VERSION ""

NS_ :

BS_:

BU_: TelemLeader IMU_FR IMU_Back IMU_FL Suspension_FR Suspension_Back Suspension_FL Suspension_Specials Pitot_FR Pitot_FL WheelRPM_FR WheelRPM_Back WheelRPM_FL RideHeight_FR RideHeight_Back RideHeight_FL Temp_Center Array

BO_ 2147487744 TelemLeader_Center: 2 TelemLeader
 SG_ Timestamp : 0|16@1+ (1,0) [0|65535] "" Vector__XXX

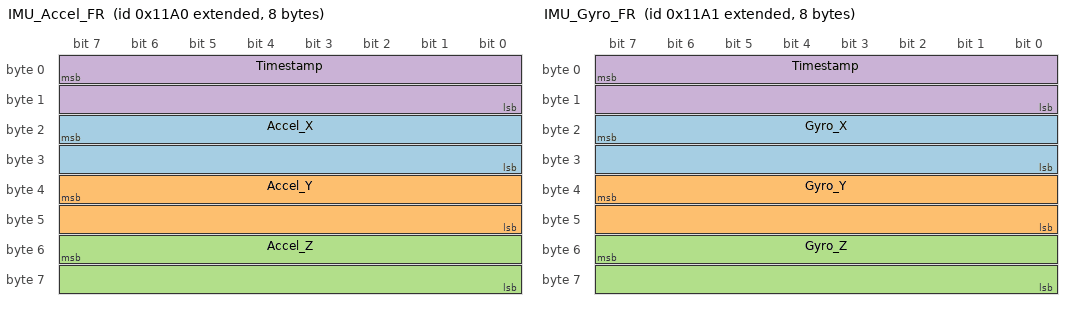
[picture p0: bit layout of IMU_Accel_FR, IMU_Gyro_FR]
BO_ 2147488160 IMU_Accel_FR: 8 IMU_FR
 SG_ Accel_X : 23|16@0- (0.000122,0) [-3.997696|3.997574] "g" Vector__XXX
 SG_ Accel_Y : 39|16@0- (0.000122,0) [-3.997696|3.997574] "g" Vector__XXX
 SG_ Accel_Z : 55|16@0- (0.000122,0) [-3.997696|3.997574] "g" Vector__XXX
 SG_ Timestamp : 7|16@0+ (1,0) [0|65535] "" Vector__XXX

BO_ 2147488161 IMU_Gyro_FR: 8 IMU_FR
 SG_ Gyro_X : 23|16@0- (0.00875,0) [-286.72|286.71125] "dps" Vector__XXX
 SG_ Gyro_Y : 39|16@0- (0.00875,0) [-286.72|286.71125] "dps" Vector__XXX
 SG_ Gyro_Z : 55|16@0- (0.00875,0) [-286.72|286.71125] "dps" Vector__XXX
 SG_ Timestamp : 7|16@0+ (1,0) [0|65535] "" Vector__XXX

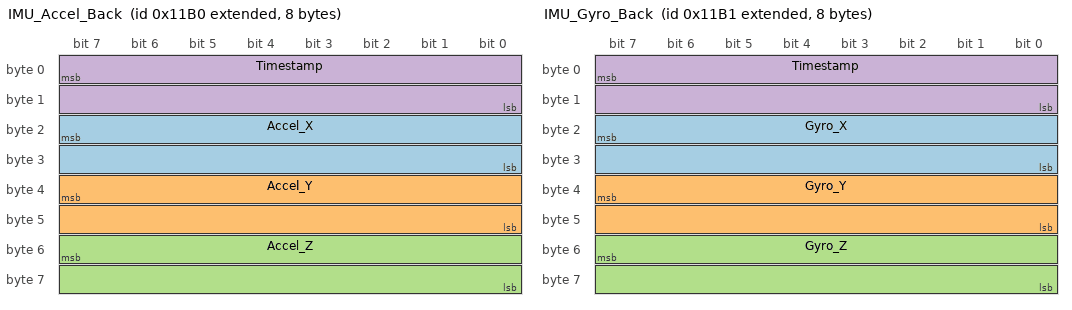
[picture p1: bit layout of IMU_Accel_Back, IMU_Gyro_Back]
BO_ 2147488176 IMU_Accel_Back: 8 IMU_Back
 SG_ Accel_X : 23|16@0- (0.000122,0) [-3.997696|3.997574] "" Vector__XXX
 SG_ Accel_Y : 39|16@0- (0.000122,0) [-3.997696|3.997574] "" Vector__XXX
 SG_ Accel_Z : 55|16@0- (0.000122,0) [-3.997696|3.997574] "" Vector__XXX
 SG_ Timestamp : 7|16@0+ (1,0) [0|65535] "" Vector__XXX

BO_ 2147488177 IMU_Gyro_Back: 8 IMU_Back
 SG_ Gyro_X : 23|16@0- (0.00875,0) [-286.72|286.71125] "" Vector__XXX
 SG_ Gyro_Y : 39|16@0- (0.00875,0) [-286.72|286.71125] "" Vector__XXX
 SG_ Gyro_Z : 55|16@0- (0.00875,0) [-286.72|286.71125] "" Vector__XXX
 SG_ Timestamp : 7|16@0+ (1,0) [0|65535] "" Vector__XXX

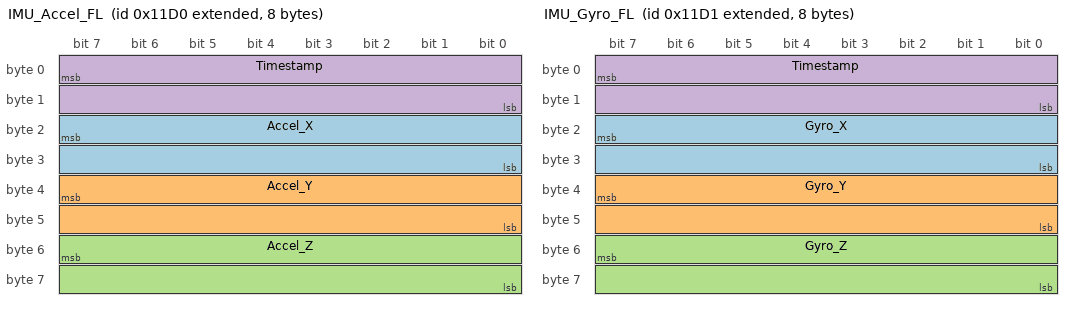
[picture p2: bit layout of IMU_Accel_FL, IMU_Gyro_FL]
BO_ 2147488208 IMU_Accel_FL: 8 IMU_FL
 SG_ Accel_X : 23|16@0- (0.000122,0) [-3.997696|3.997574] "" Vector__XXX
 SG_ Accel_Y : 39|16@0- (0.000122,0) [-3.997696|3.997574] "" Vector__XXX
 SG_ Accel_Z : 55|16@0- (0.000122,0) [-3.997696|3.997574] "" Vector__XXX
 SG_ Timestamp : 7|16@0+ (1,0) [0|65535] "" Vector__XXX

BO_ 2147488209 IMU_Gyro_FL: 8 IMU_FL
 SG_ Gyro_X : 23|16@0- (0.00875,0) [-286.72|286.71125] "" Vector__XXX
 SG_ Gyro_Y : 39|16@0- (0.00875,0) [-286.72|286.71125] "" Vector__XXX
 SG_ Gyro_Z : 55|16@0- (0.00875,0) [-286.72|286.71125] "" Vector__XXX
 SG_ Timestamp : 7|16@0+ (1,0) [0|65535] "" Vector__XXX

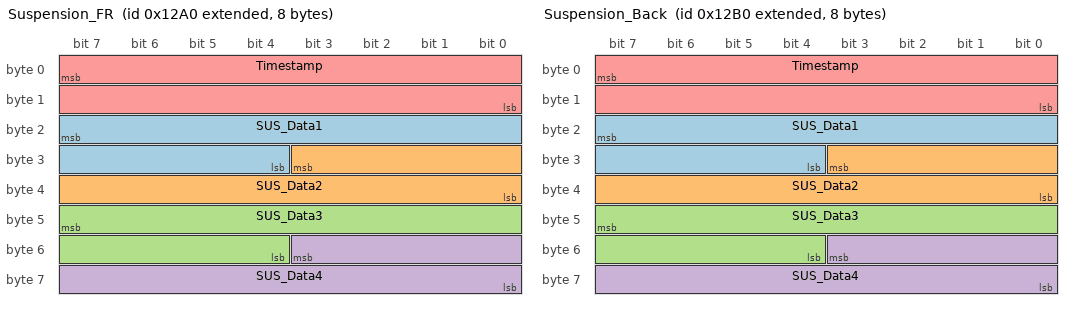
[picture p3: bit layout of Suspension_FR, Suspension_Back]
BO_ 2147488416 Suspension_FR: 8 Suspension_FR
 SG_ SUS_Data1 : 23|12@0+ (0.0188885,1) [0|78.367296] "mm" Vector__XXX
 SG_ SUS_Data2 : 27|12@0+ (0.0188885,1) [0|78.367296] "mm" Vector__XXX
 SG_ SUS_Data3 : 47|12@0+ (0.0188885,1) [0|78.367296] "mm" Vector__XXX
 SG_ SUS_Data4 : 51|12@0+ (0.0188885,1) [0|78.367296] "mm" Vector__XXX
 SG_ Timestamp : 7|16@0+ (1,0) [0|65535] "" Vector__XXX

BO_ 2147488432 Suspension_Back: 8 Suspension_Back
 SG_ SUS_Data1 : 23|12@0+ (0.0188885,1) [0|78.367296] "mm" Vector__XXX
 SG_ SUS_Data2 : 27|12@0+ (0.0188885,1) [0|78.367296] "mm" Vector__XXX
 SG_ SUS_Data3 : 47|12@0+ (0.0188885,1) [0|78.367296] "mm" Vector__XXX
 SG_ SUS_Data4 : 51|12@0+ (0.0188885,1) [0|78.367296] "mm" Vector__XXX
 SG_ Timestamp : 7|16@0+ (1,0) [0|65535] "" Vector__XXX

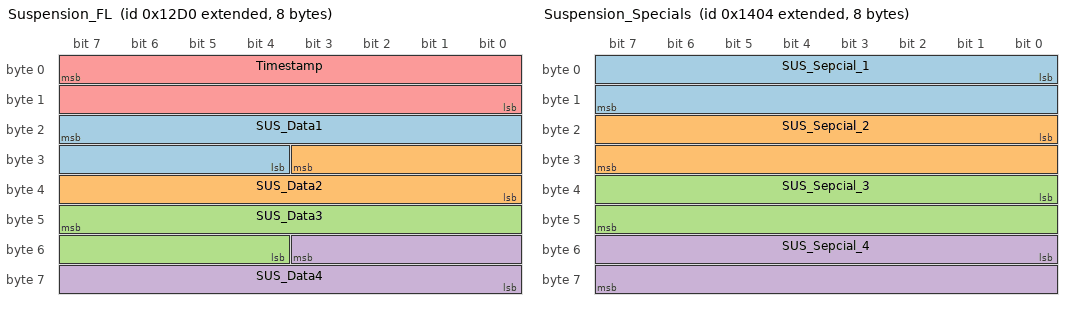
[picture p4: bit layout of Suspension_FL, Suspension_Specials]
BO_ 2147488464 Suspension_FL: 8 Suspension_FL
 SG_ SUS_Data1 : 23|12@0+ (0.0188885,1) [0|78.367296] "mm" Vector__XXX
 SG_ SUS_Data2 : 27|12@0+ (0.0188885,1) [0|78.367296] "mm" Vector__XXX
 SG_ SUS_Data3 : 47|12@0+ (0.0188885,1) [0|78.367296] "mm" Vector__XXX
 SG_ SUS_Data4 : 51|12@0+ (0.0188885,1) [0|78.367296] "mm" Vector__XXX
 SG_ Timestamp : 7|16@0+ (1,0) [0|65535] "" Vector__XXX

BO_ 2147488772 Suspension_Specials: 8 Suspension_Specials
 SG_ SUS_Sepcial_1 : 0|16@1+ (1,0) [0|65535] "" Vector__XXX
 SG_ SUS_Sepcial_2 : 16|16@1+ (1,0) [0|65535] "" Vector__XXX
 SG_ SUS_Sepcial_3 : 32|16@1+ (1,0) [0|65535] "" Vector__XXX
 SG_ SUS_Sepcial_4 : 48|16@1+ (1,0) [0|65535] "" Vector__XXX

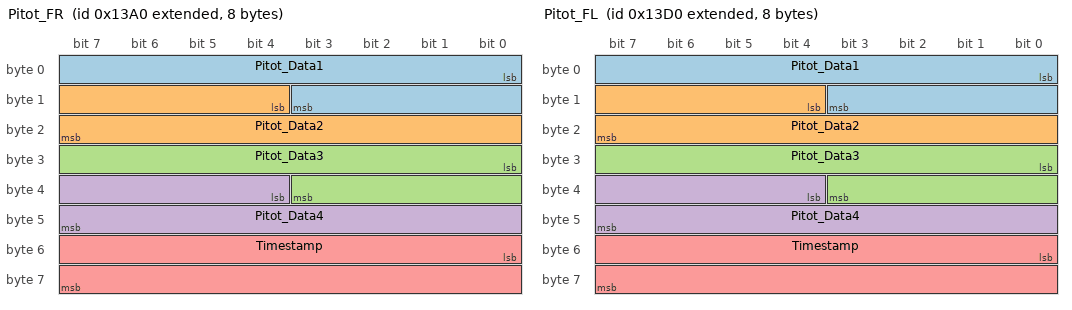
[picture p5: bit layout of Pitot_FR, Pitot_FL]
BO_ 2147488672 Pitot_FR: 8 Pitot_FR
 SG_ Pitot_Data1 : 0|12@1+ (1,0) [0|4095] "" Vector__XXX
 SG_ Pitot_Data2 : 12|12@1+ (1,0) [0|4095] "" Vector__XXX
 SG_ Pitot_Data3 : 24|12@1+ (1,0) [0|4095] "" Vector__XXX
 SG_ Pitot_Data4 : 36|12@1+ (1,0) [0|4095] "" Vector__XXX
 SG_ Timestamp : 48|16@1+ (1,0) [0|65535] "" Vector__XXX

BO_ 2147488720 Pitot_FL: 8 Pitot_FL
 SG_ Pitot_Data1 : 0|12@1+ (1,0) [0|4095] "" Vector__XXX
 SG_ Pitot_Data2 : 12|12@1+ (1,0) [0|4095] "" Vector__XXX
 SG_ Pitot_Data3 : 24|12@1+ (1,0) [0|4095] "" Vector__XXX
 SG_ Pitot_Data4 : 36|12@1+ (1,0) [0|4095] "" Vector__XXX
 SG_ Timestamp : 48|16@1+ (1,0) [0|65535] "" Vector__XXX

BO_ 2147488928 WheelRPM_FR: 8 WheelRPM_FR
 SG_ Timestamp : 7|16@0+ (1,0) [0|65535] "" Vector__XXX
 SG_ RPM : 23|16@0+ (1,0) [0|65535] "rpm" Vector__XXX

BO_ 2147488960 WheelRPM_Back: 4 WheelRPM_Back
 SG_ Timestamp : 7|16@0+ (1,0) [0|65535] "" Vector__XXX
 SG_ RPM : 23|16@0+ (1,0) [0|65535] "rpm" Vector__XXX

BO_ 2147488976 WheelRPM_FL: 8 WheelRPM_FL
 SG_ Timestamp : 7|16@0+ (1,0) [0|65535] "" Vector__XXX
 SG_ RPM : 23|16@0+ (1,0) [0|65535] "rpm" Vector__XXX

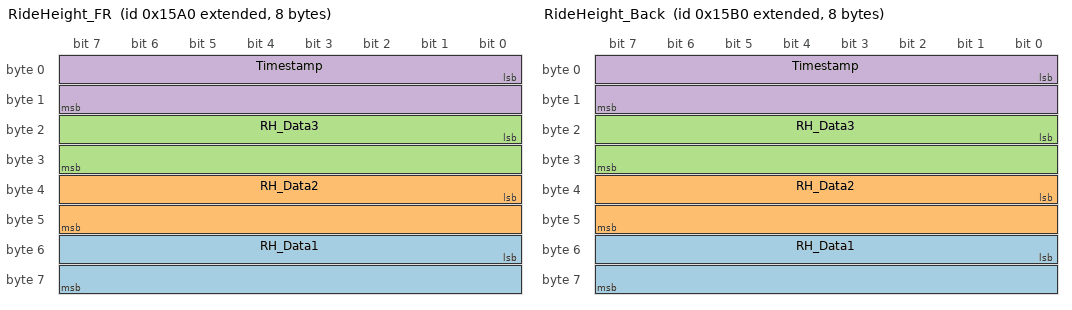
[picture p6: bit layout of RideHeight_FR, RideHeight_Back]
BO_ 2147489184 RideHeight_FR: 8 RideHeight_FR
 SG_ RH_Data1 : 48|16@1+ (0.01,0) [0|655.36] "cm" Vector__XXX
 SG_ RH_Data2 : 32|16@1+ (0.01,0) [0|655.36] "cm" Vector__XXX
 SG_ RH_Data3 : 16|16@1+ (0.01,0) [0|655.36] "cm" Vector__XXX
 SG_ Timestamp : 0|16@1+ (1,0) [0|65535] "" Vector__XXX

BO_ 2147489200 RideHeight_Back: 8 RideHeight_Back
 SG_ RH_Data1 : 48|16@1+ (0.01,0) [0|655.36] "cm" Vector__XXX
 SG_ RH_Data2 : 32|16@1+ (0.01,0) [0|655.36] "cm" Vector__XXX
 SG_ RH_Data3 : 16|16@1+ (0.01,0) [0|655.36] "cm" Vector__XXX
 SG_ Timestamp : 0|16@1+ (1,0) [0|65535] "" Vector__XXX

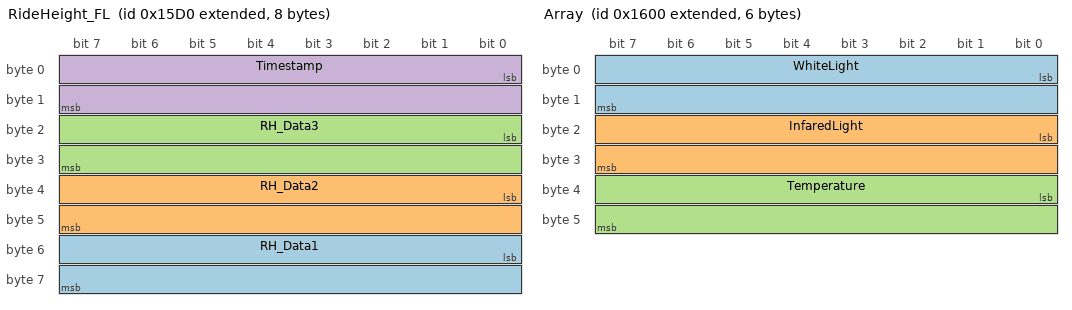
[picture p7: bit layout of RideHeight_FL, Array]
BO_ 2147489232 RideHeight_FL: 8 RideHeight_FL
 SG_ RH_Data1 : 48|16@1+ (0.01,0) [0|655.36] "cm" Vector__XXX
 SG_ RH_Data2 : 32|16@1+ (0.01,0) [0|655.36] "cm" Vector__XXX
 SG_ RH_Data3 : 16|16@1+ (0.01,0) [0|655.36] "cm" Vector__XXX
 SG_ Timestamp : 0|16@1+ (1,0) [0|65535] "" Vector__XXX

BO_ 2147489280 Array: 6 Array
 SG_ WhiteLight : 0|16@1+ (1,0) [0|65535] "" Vector__XXX
 SG_ InfaredLight : 16|16@1+ (1,0) [0|65535] "" Vector__XXX
 SG_ Temperature : 32|16@1+ (1,0) [0|65535] "" Vector__XXX

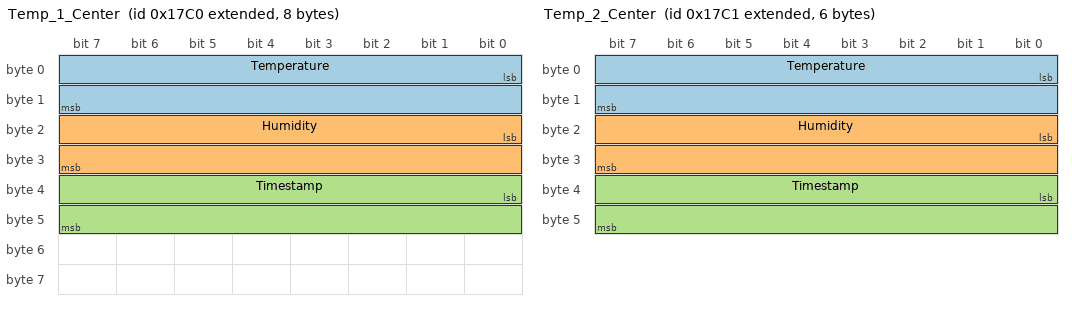
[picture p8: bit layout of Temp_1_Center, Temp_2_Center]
BO_ 2147489728 Temp_1_Center: 8 Temp_Center
 SG_ Temperature : 0|16@1+ (1,0) [0|65535] "" Vector__XXX
 SG_ Humidity : 16|16@1+ (1,0) [0|65535] "" Vector__XXX
 SG_ Timestamp : 32|16@1+ (1,0) [0|65535] "" Vector__XXX

BO_ 2147489729 Temp_2_Center: 6 Temp_Center
 SG_ Temperature : 0|16@1- (1,0) [-32768|32767] "" Vector__XXX
 SG_ Humidity : 16|16@1+ (1,0) [0|65535] "" Vector__XXX
 SG_ Timestamp : 32|16@1+ (1,0) [0|65535] "" Vector__XXX

BO_ 2147489730 FR_IMU_Temp: 4 IMU_FR
 SG_ Temperature : 23|16@0- (0.00703125,77) [-40|180] "" Vector__XXX
 SG_ Timestamp : 7|16@0+ (1,0) [0|65535] "" Vector__XXX

BO_ 2147489731 FL_IMU_Temp: 4 IMU_FL
 SG_ Temperature : 23|16@0- (0.00703125,77) [-40|180] "" Vector__XXX
 SG_ Timestamp : 7|16@0+ (1,0) [0|65535] "" Vector__XXX

BO_ 2147489732 B_IMU_Temp: 4 IMU_Back
 SG_ Temperature : 23|16@0- (0.00703125,77) [-40|180] "" Vector__XXX
 SG_ Timestamp : 7|16@0+ (1,0) [0|65535] "" Vector__XXX

CM_ BO_ 4096 "Telem Leader Node. GPS moved to HighNoon/GPS.dbc (Photon gps_car / staging 0x10C0/0x10C1).";
CM_ "Merged from Photon UIPPlotsStaging HighNoon.dbc DAQ + telem_rev1 Suspension_Specials; IMU scales/temps from latest HighNoon telemetry. Server/DAqCAN IDs are telem-bus StdId + 0x1000 (extended). Suspension_* SUS_Data scale/offset/unit (mm) and RideHeight_* RH_Data scale/unit (cm) from CARCan+TelemCAN.dbc calibration; message/signal names kept. Array 0x1600 (WhiteLight/InfaredLight/Temperature) added from same source. WheelRPM_FR/FL kept as FSGP last-day wire = VCAT-WheelsBoard-Software WheelsCodek DLC8: ts u16 BE (bytes 0-1) + rpm u16 BE (bytes 2-3), bytes 4-7 unused — not the swapped DLC4 layout in CARCan+TelemCAN.dbc. WheelRPM_Back 0x14C0 = bus 0x4C0, DLC4 ts u16 BE + rpm u16 BE. NOTE: on 2026-07-23 the FR/FL hall payload is a free-running counter (rpm sensor likely disconnected) so RPM decodes cleanly but is not physical.";
CM_ BO_ 5280 "Wheel RPM front-right. Telem bus StdId 0x4A0 (FixedWheelsCode hallID) -> server 0x14A0.";
CM_ BO_ 5312 "Wheel RPM back/rear. Telem bus StdId 0x4C0 -> server 0x14C0. Not in Photon daq.dbc; present on FSGP wire.";
CM_ BO_ 5328 "Wheel RPM front-left. Telem bus StdId 0x4D0 (WheelsCodek CAN_ID_HALL) -> server 0x14D0.";

BA_DEF_  "DBName" STRING ;
BA_DEF_ BO_  "GenMsgSendType" ENUM  "Cyclic","Event","CyclicAndEvent","CyclicAndEventNoRepetition","None","Spontaneous";
BA_DEF_ BO_  "VFrameFormat" ENUM  "StandardCAN","ExtendedCAN","reserved","J1939PG","reserved","reserved","reserved","reserved","reserved","reserved","reserved","reserved","reserved","reserved","StandardCAN_FD","ExtendedCAN_FD";
BA_DEF_  "BusType" STRING ;
BA_DEF_DEF_  "DBName" "";
BA_DEF_DEF_  "GenMsgSendType" "Cyclic";
BA_DEF_DEF_  "VFrameFormat" "ExtendedCAN";
BA_DEF_DEF_  "BusType" "";
BA_ "BusType" "CAN";
BA_ "DBName" "DAqCAN";
